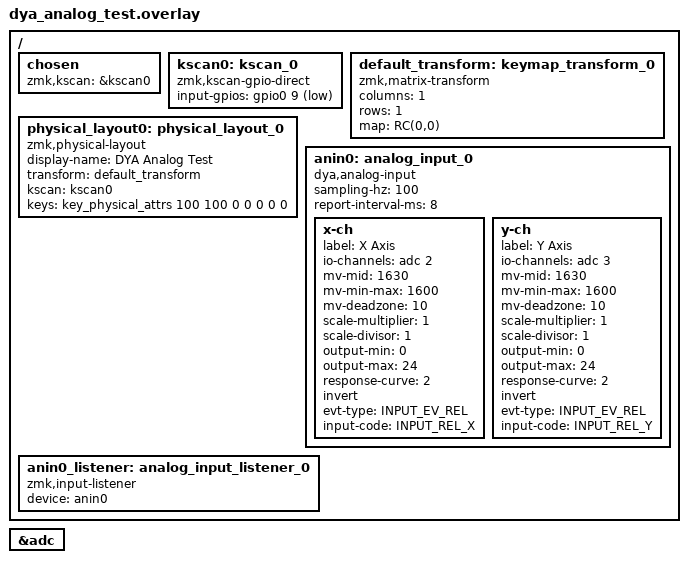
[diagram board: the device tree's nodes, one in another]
#include <zephyr/dt-bindings/input/input-event-codes.h>
#include <dt-bindings/zmk/matrix_transform.h>
#include <physical_layouts.dtsi>

&adc {
    status = "okay";
};

/ {
    chosen {
        zmk,kscan = &kscan0;
    };

    kscan0: kscan_0 {
        compatible = "zmk,kscan-gpio-direct";
        input-gpios = <&gpio0 9 (GPIO_ACTIVE_LOW | GPIO_PULL_UP)>;
    };

    default_transform: keymap_transform_0 {
        compatible = "zmk,matrix-transform";
        columns = <1>;
        rows = <1>;
        map = <RC(0,0)>;
    };

    physical_layout0: physical_layout_0 {
        compatible = "zmk,physical-layout";
        display-name = "DYA Analog Test";
        transform = <&default_transform>;
        kscan = <&kscan0>;
        keys = <&key_physical_attrs 100 100 0 0 0 0 0>;
    };

    anin0: analog_input_0 {
        compatible = "dya,analog-input";
        sampling-hz = <100>;
        report-interval-ms = <8>;

        x-ch {
            label = "X Axis";
            io-channels = <&adc 2>;
            mv-mid = <1630>;
            mv-min-max = <1600>;
            mv-deadzone = <10>;
            scale-multiplier = <1>;
            scale-divisor = <1>;
            output-min = <0>;
            output-max = <24>;
            response-curve = <2>;
            invert;
            evt-type = <INPUT_EV_REL>;
            input-code = <INPUT_REL_X>;
        };

        y-ch {
            label = "Y Axis";
            io-channels = <&adc 3>;
            mv-mid = <1630>;
            mv-min-max = <1600>;
            mv-deadzone = <10>;
            scale-multiplier = <1>;
            scale-divisor = <1>;
            output-min = <0>;
            output-max = <24>;
            response-curve = <2>;
            invert;
            evt-type = <INPUT_EV_REL>;
            input-code = <INPUT_REL_Y>;
        };
    };

    anin0_listener: analog_input_listener_0 {
        compatible = "zmk,input-listener";
        device = <&anin0>;
    };
};
